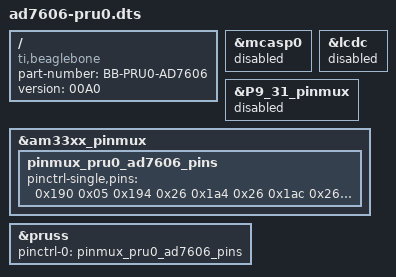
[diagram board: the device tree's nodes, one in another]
/dts-v1/;
/plugin/;

/*
 * Device Tree Overlay for AD7606 ADC with PRU0
 *
 * This overlay configures the BeagleBone Black PRU0 pins for interfacing
 * with the AD7606 16-bit, 8-channel simultaneous sampling ADC.
 *
 * Pin Mapping (BeagleBone Black P9 Header):
 * ==========================================
 * Signal    | BBB Pin | PRU Pin      | Direction | Description
 * ----------|---------|--------------|-----------|---------------------------
 * CONVST    | P9.31   | PRU0 R30.0   | Output    | Convert Start (trigger ADC)
 * BUSY      | P9.29   | PRU0 R31.0   | Input     | Conversion in progress
 * D0        | P9.27   | PRU0 R31.1   | Input     | Data bit 0 (LSB)
 * D1        | P9.25   | PRU0 R31.2   | Input     | Data bit 1
 * D2        | P9.28   | PRU0 R31.3   | Input     | Data bit 2
 * D3        | P9.30   | PRU0 R31.4   | Input     | Data bit 3
 * D4        | P9.92   | PRU0 R31.5   | Input     | Data bit 4
 * D5        | P9.42   | PRU0 R31.6   | Input     | Data bit 5
 * D6        | P9.91   | PRU0 R31.7   | Input     | Data bit 6
 * D7        | P9.41   | PRU0 R31.8   | Input     | Data bit 7
 * D8        | P8.45   | PRU0 R31.9   | Input     | Data bit 8
 * D9        | P8.46   | PRU0 R31.10  | Input     | Data bit 9
 * D10       | P8.43   | PRU0 R31.11  | Input     | Data bit 10
 * D11       | P8.44   | PRU0 R31.12  | Input     | Data bit 11
 * D12       | P8.41   | PRU0 R31.13  | Input     | Data bit 12
 * D13       | P8.42   | PRU0 R31.14  | Input     | Data bit 13
 * D14       | P8.39   | PRU0 R31.15  | Input     | Data bit 14
 * D15       | P8.40   | PRU0 R31.16  | Input     | Data bit 15 (MSB)
 *
 * Notes:
 * - McASP (audio) must be disabled so it releases PRU pins (e.g. PIN100).
 * - HDMI (LCD controller) must be disabled to free P8 LCD data pins.
 * - PRU0 R30 register is used for outputs (CONVST).
 * - PRU0 R31 register is used for inputs (BUSY and 16-bit parallel data).
 * - Uses U-Boot overlays; no bone_capemgr.
 */

/ {
    compatible = "ti,beaglebone", "ti,beaglebone-black";
    part-number = "BB-PRU0-AD7606";
    version = "00A0";

    /*
     * Fragment 0 – Disable McASP (audio steals PRU pins, e.g. PIN100)
     */
    fragment@0 {
        target = <&mcasp0>;
        __overlay__ {
            status = "disabled";
        };
    };

    /*
     * Fragment 1 – Disable HDMI (LCD controller)
     */
    fragment@1 {
        target = <&lcdc>;
        __overlay__ {
            status = "disabled";
        };
    };

    /*
     * Fragment 2 – Release P9.31 from ocp:P9_31_pinmux so PRU can claim PIN100
     */
    fragment@2 {
        target = <&P9_31_pinmux>;
        __overlay__ {
            status = "disabled";
        };
    };

    /*
     * Fragment 3 – PRU pinmux (0x05 = output, 0x26 = input pull-down, MODE5/6 = PRU)
     */
    fragment@3 {
        target = <&am33xx_pinmux>;
        __overlay__ {
            pinmux_pru0_ad7606_pins: pinmux_pru0_ad7606_pins {
                pinctrl-single,pins = <
                    /* CONVST  (P9.31) PRU0_R30_0 */
                    0x190 0x05

                    /* BUSY    (P9.29) PRU0_R31_0 */
                    0x194 0x26

                    /* D0–D7 */
                    0x1a4 0x26  /* P9.27 */
                    0x1ac 0x26  /* P9.25 */
                    0x19c 0x26  /* P9.28 */
                    0x198 0x26  /* P9.30 */
                    0x1a0 0x26  /* P9.92 */
                    0x164 0x26  /* P9.42 */
                    0x1a8 0x26  /* P9.91 */
                    0x1b4 0x26  /* P9.41 */

                    /* D8–D15 */
                    0x0a0 0x26  /* P8.45 */
                    0x0a4 0x26  /* P8.46 */
                    0x0a8 0x26  /* P8.43 */
                    0x0ac 0x26  /* P8.44 */
                    0x0b0 0x26  /* P8.41 */
                    0x0b4 0x26  /* P8.42 */
                    0x0b8 0x26  /* P8.39 */
                    0x0bc 0x26  /* P8.40 */
                >;
            };
        };
    };

    /*
     * Fragment 4 – Enable PRU and apply pins
     */
    fragment@4 {
        target = <&pruss>;
        __overlay__ {
            status = "okay";
            pinctrl-names = "default";
            pinctrl-0 = <&pinmux_pru0_ad7606_pins>;
        };
    };
};
